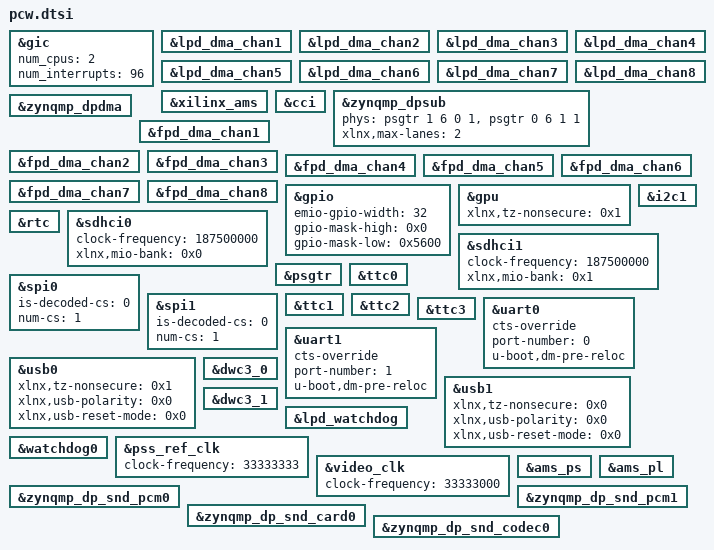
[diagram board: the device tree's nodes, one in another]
/*
 * CAUTION: This file is automatically generated by Xilinx.
 * Version: XSCT 2023.2
 * Today is: Sat Apr 27 20:04:09 2024
 */


&gic {
	num_cpus = <2>;
	num_interrupts = <96>;
};
&lpd_dma_chan1 {
	status = "okay";
};
&lpd_dma_chan2 {
	status = "okay";
};
&lpd_dma_chan3 {
	status = "okay";
};
&lpd_dma_chan4 {
	status = "okay";
};
&lpd_dma_chan5 {
	status = "okay";
};
&lpd_dma_chan6 {
	status = "okay";
};
&lpd_dma_chan7 {
	status = "okay";
};
&lpd_dma_chan8 {
	status = "okay";
};
&xilinx_ams {
	status = "okay";
};
&cci {
	status = "okay";
};
&zynqmp_dpsub {
	phy-names = "dp-phy0","dp-phy1";
	phys = <&psgtr 1 6 0 1>, <&psgtr 0 6 1 1>;
	status = "okay";
	xlnx,max-lanes = <2>;
};
&zynqmp_dpdma {
	status = "okay";
};
&fpd_dma_chan1 {
	status = "okay";
};
&fpd_dma_chan2 {
	status = "okay";
};
&fpd_dma_chan3 {
	status = "okay";
};
&fpd_dma_chan4 {
	status = "okay";
};
&fpd_dma_chan5 {
	status = "okay";
};
&fpd_dma_chan6 {
	status = "okay";
};
&fpd_dma_chan7 {
	status = "okay";
};
&fpd_dma_chan8 {
	status = "okay";
};
&gpio {
	emio-gpio-width = <32>;
	gpio-mask-high = <0x0>;
	gpio-mask-low = <0x5600>;
	status = "okay";
};
&gpu {
	status = "okay";
	xlnx,tz-nonsecure = <0x1>;
};
&i2c1 {
	status = "okay";
};
&rtc {
	status = "okay";
};
&sdhci0 {
	clock-frequency = <187500000>;
	status = "okay";
	xlnx,mio-bank = <0x0>;
};
&sdhci1 {
	clock-frequency = <187500000>;
	status = "okay";
	xlnx,mio-bank = <0x1>;
};
&psgtr {
	status = "okay";
};
&spi0 {
	is-decoded-cs = <0>;
	num-cs = <1>;
	status = "okay";
};
&spi1 {
	is-decoded-cs = <0>;
	num-cs = <1>;
	status = "okay";
};
&ttc0 {
	status = "okay";
};
&ttc1 {
	status = "okay";
};
&ttc2 {
	status = "okay";
};
&ttc3 {
	status = "okay";
};
&uart0 {
	cts-override ;
	device_type = "serial";
	port-number = <0>;
	status = "okay";
	u-boot,dm-pre-reloc ;
};
&uart1 {
	cts-override ;
	device_type = "serial";
	port-number = <1>;
	status = "okay";
	u-boot,dm-pre-reloc ;
};
&usb0 {
	status = "okay";
	xlnx,tz-nonsecure = <0x1>;
	xlnx,usb-polarity = <0x0>;
	xlnx,usb-reset-mode = <0x0>;
};
&usb1 {
	status = "okay";
	xlnx,tz-nonsecure = <0x0>;
	xlnx,usb-polarity = <0x0>;
	xlnx,usb-reset-mode = <0x0>;
};
&dwc3_0 {
	status = "okay";
};
&dwc3_1 {
	status = "okay";
};
&lpd_watchdog {
	status = "okay";
};
&watchdog0 {
	status = "okay";
};
&pss_ref_clk {
	clock-frequency = <33333333>;
};
&video_clk {
	clock-frequency = <33333000>;
};
&ams_ps {
	status = "okay";
};
&ams_pl {
	status = "okay";
};
&zynqmp_dp_snd_pcm0 {
	status = "okay";
};
&zynqmp_dp_snd_pcm1 {
	status = "okay";
};
&zynqmp_dp_snd_card0 {
	status = "okay";
};
&zynqmp_dp_snd_codec0 {
	status = "okay";
};
